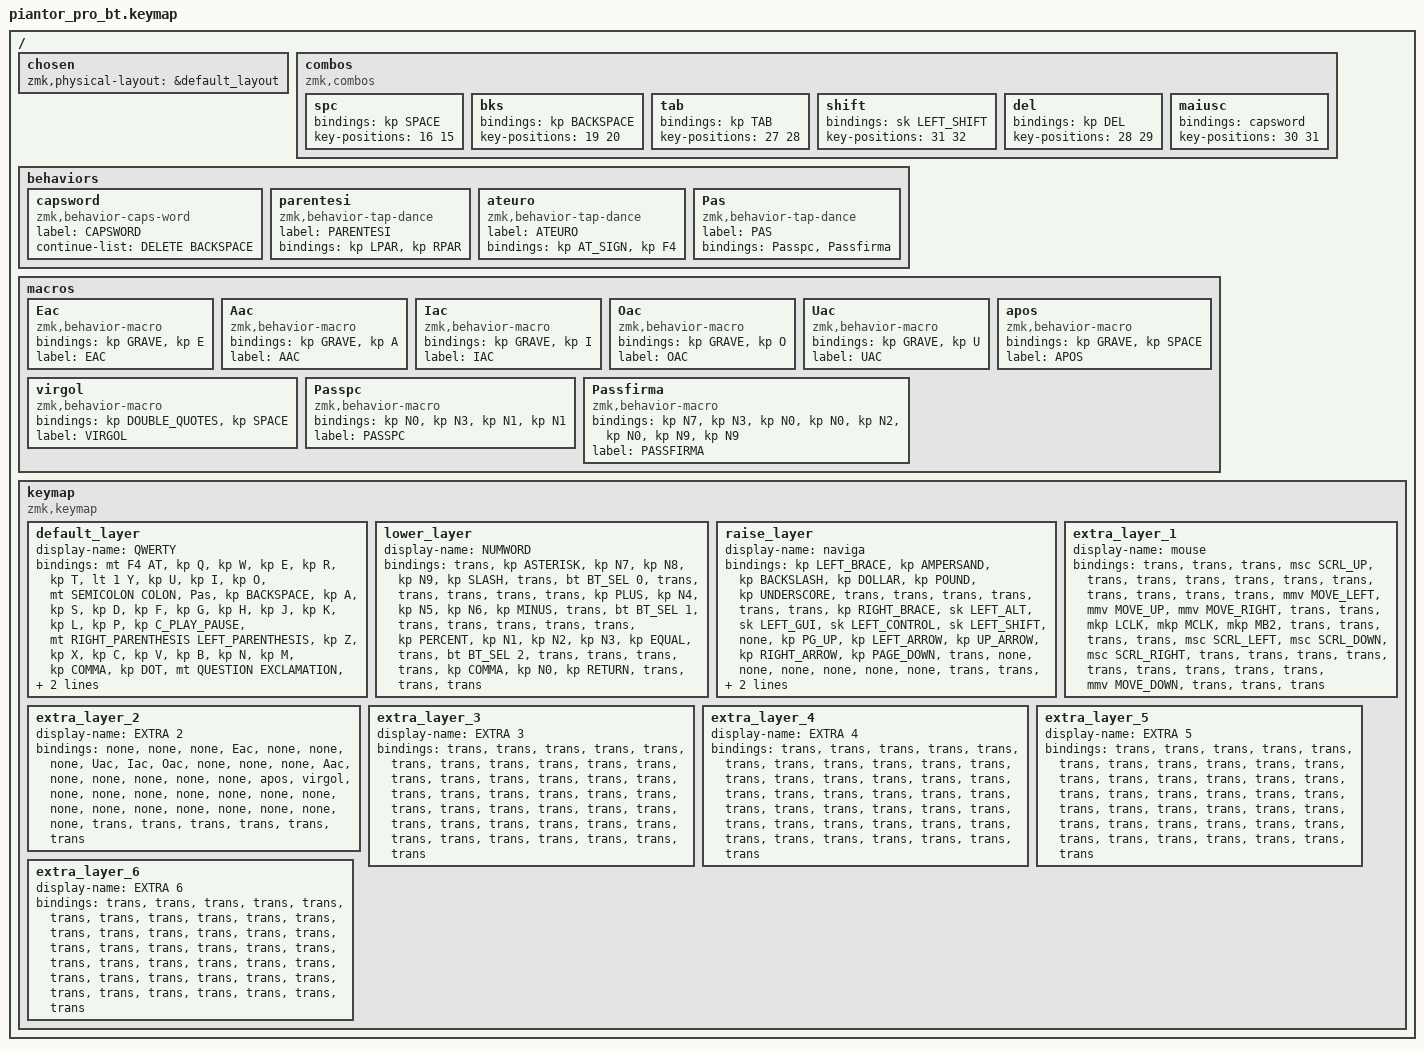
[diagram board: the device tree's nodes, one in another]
/*
 * Copyright (c) 2020 The ZMK Contributors
 *
 * SPDX-License-Identifier: MIT
 */

#define ZMK_POINTING_DEFAULT_MOVE_VAL 1500  // default: 600
#define ZMK_POINTING_DEFAULT_SCRL_VAL 20    // default: 10

#include <behaviors/num_word.dtsi>
#include <behaviors/num_word.dtsi>
#include <behaviors.dtsi>
#include <dt-bindings/zmk/bt.h>
#include <dt-bindings/zmk/keys.h>
#include <dt-bindings/zmk/pointing.h>

/ {
    chosen { zmk,physical-layout = &default_layout; };
};

/ {
    combos {
        compatible = "zmk,combos";

        spc {
            bindings = <&kp SPACE>;
            key-positions = <16 15>;
        };

        bks {
            bindings = <&kp BACKSPACE>;
            key-positions = <19 20>;
        };

        tab {
            bindings = <&kp TAB>;
            key-positions = <27 28>;
        };

        shift {
            bindings = <&sk LEFT_SHIFT>;
            key-positions = <31 32>;
        };

        del {
            bindings = <&kp DEL>;
            key-positions = <28 29>;
        };

        maiusc {
            bindings = <&capsword>;
            key-positions = <30 31>;
        };
    };

    behaviors {
        capsword: capsword {
            compatible = "zmk,behavior-caps-word";
            label = "CAPSWORD";
            #binding-cells = <0>;
            continue-list = <DELETE BACKSPACE>;
        };

        parentesi: parentesi {
            compatible = "zmk,behavior-tap-dance";
            label = "PARENTESI";
            #binding-cells = <0>;
            bindings = <&kp LPAR>, <&kp RPAR>;
        };

        ateuro: ateuro {
            compatible = "zmk,behavior-tap-dance";
            label = "ATEURO";
            #binding-cells = <0>;
            bindings = <&kp AT_SIGN>, <&kp F4>;
        };

        Pas: Pas {
            compatible = "zmk,behavior-tap-dance";
            label = "PAS";
            #binding-cells = <0>;
            bindings = <&Passpc>, <&Passfirma>;
        };
    };

    behaviors {
    };

    macros {
        Eac: Eac {
            compatible = "zmk,behavior-macro";
            #binding-cells = <0>;
            bindings = <&kp GRAVE &kp E>;
            label = "EAC";
        };

        Aac: Aac {
            compatible = "zmk,behavior-macro";
            #binding-cells = <0>;
            bindings = <&kp GRAVE &kp A>;
            label = "AAC";
        };

        Iac: Iac {
            compatible = "zmk,behavior-macro";
            #binding-cells = <0>;
            bindings = <&kp GRAVE &kp I>;
            label = "IAC";
        };

        Oac: Oac {
            compatible = "zmk,behavior-macro";
            #binding-cells = <0>;
            bindings = <&kp GRAVE &kp O>;
            label = "OAC";
        };

        Uac: Uac {
            compatible = "zmk,behavior-macro";
            #binding-cells = <0>;
            bindings = <&kp GRAVE &kp U>;
            label = "UAC";
        };

        apos: apos {
            compatible = "zmk,behavior-macro";
            #binding-cells = <0>;
            bindings = <&kp GRAVE &kp SPACE>;
            label = "APOS";
        };

        virgol: virgol {
            compatible = "zmk,behavior-macro";
            #binding-cells = <0>;
            bindings = <&kp DOUBLE_QUOTES &kp SPACE>;
            label = "VIRGOL";
        };

        Passpc: Passpc {
            compatible = "zmk,behavior-macro";
            #binding-cells = <0>;
            bindings = <&kp N0 &kp N3 &kp N1 &kp N1>;
            label = "PASSPC";
        };

        Passfirma: Passfirma {
            compatible = "zmk,behavior-macro";
            #binding-cells = <0>;
            bindings = <&kp N7 &kp N3 &kp N0 &kp N0 &kp N2 &kp N0 &kp N9 &kp N9>;
            label = "PASSFIRMA";
        };
    };

    keymap {
        compatible = "zmk,keymap";

        default_layer {
            display-name = "QWERTY";

            // --------------------------------------------------------------------------------
            // |  TAB |  Q  |  W  |  E  |  R  |  T  |  Y  |  U   |  I  |  O  |  P  | BSPC |
            // | CTRL |  A  |  S  |  D  |  F  |  G  |  H  |  J   |  K  |  L  |  ;  |  '   |
            // | SHFT |  Z  |  X  |  C  |  V  |  B  |  N  |  M   |  ,  |  .  |  /  | ESC  |
            //                    | GUI | LWR | SPC | ENT | RSE  | ALT |

            bindings = <
&mt F4 AT  &kp Q  &kp W  &kp E  &kp R  &kp T  &lt 1 Y  &kp U  &kp I  &kp O  &mt SEMICOLON COLON  &Pas  &kp BACKSPACE  &kp A  &kp S  &kp D  &kp F  &kp G  &kp H  &kp J  &kp K  &kp L  &kp P  &kp C_PLAY_PAUSE  &mt RIGHT_PARENTHESIS LEFT_PARENTHESIS  &kp Z  &kp X  &kp C  &kp V  &kp B  &kp N  &kp M  &kp COMMA  &kp DOT  &mt QUESTION EXCLAMATION  &mt C_VOLUME_UP C_VOL_DN  &num_word 1  &kp ESC  &lt 2 ENTER  &sl 4  &kp LEFT_CONTROL  &tog 3
            >;
        };

        lower_layer {
            display-name = "NUMWORD";

            // -----------------------------------------------------------------------------------------
            // |  TAB |  1  |  2  |  3  |  4  |  5    |  6  |  7  |  8  |  9  |  0  | BSPC |
            // | CTRL | BT1 | BT2 | BT3 | BT4 | BT5   | LFT | DWN |  UP | RGT |     |      |
            // | SHFT | BTCR| RGB | RST | BOOT| Unlock|     |     |     |     |     |      |
            //                    | GUI |     | SPC   | ENT |     | ALT |

            bindings = <
&trans  &kp ASTERISK  &kp N7  &kp N8  &kp N9  &kp SLASH  &trans  &bt BT_SEL 0  &trans  &trans  &trans  &trans  &trans  &kp PLUS  &kp N4  &kp N5  &kp N6  &kp MINUS  &trans  &bt BT_SEL 1  &trans  &trans  &trans  &trans  &trans  &kp PERCENT  &kp N1  &kp N2  &kp N3  &kp EQUAL  &trans  &bt BT_SEL 2  &trans  &trans  &trans  &trans  &kp COMMA  &kp N0  &kp RETURN  &trans  &trans  &trans
            >;
        };

        raise_layer {
            display-name = "naviga";

            // -----------------------------------------------------------------------------------------
            // |  TAB |  !  |  @  |  #  |  $  |  %  |  ^  |  &  |  *  |  (  |  )  | BSPC |
            // | CTRL |     |     |     |     |     |  -  |  =  |  [  |  ]  |  \  |  `   |
            // | SHFT |     |     |     |     |     |  _  |  +  |  {  |  }  | "|" |  ~   |
            //                    | GUI |     | SPC | ENT |     | ALT |

            bindings = <
&kp LEFT_BRACE  &kp AMPERSAND  &kp BACKSLASH  &kp DOLLAR  &kp POUND  &kp UNDERSCORE  &trans  &trans  &trans  &trans  &trans  &trans  &kp RIGHT_BRACE  &sk LEFT_ALT  &sk LEFT_GUI  &sk LEFT_CONTROL  &sk LEFT_SHIFT  &none  &kp PG_UP  &kp LEFT_ARROW  &kp UP_ARROW  &kp RIGHT_ARROW  &kp PAGE_DOWN  &trans  &none  &none  &none  &none  &none  &none  &trans  &trans  &trans  &trans  &trans  &trans  &trans  &trans  &trans  &kp DOWN_ARROW  &trans  &trans
            >;
        };

        extra_layer_1 {
            display-name = "mouse";
            bindings = <
&trans  &trans  &trans  &msc SCRL_UP  &trans  &trans  &trans  &trans  &trans  &trans  &trans  &trans  &trans  &trans  &mmv MOVE_LEFT  &mmv MOVE_UP  &mmv MOVE_RIGHT  &trans  &trans  &mkp LCLK  &mkp MCLK  &mkp MB2  &trans  &trans  &trans  &trans  &msc SCRL_LEFT  &msc SCRL_DOWN  &msc SCRL_RIGHT  &trans  &trans  &trans  &trans  &trans  &trans  &trans  &trans  &trans  &mmv MOVE_DOWN  &trans  &trans  &trans
            >;
        };

        extra_layer_2 {
            display-name = "EXTRA 2";
            bindings = <
&none  &none  &none  &Eac  &none  &none  &none  &Uac  &Iac  &Oac  &none  &none  &none  &Aac  &none  &none  &none  &none  &none  &apos  &virgol  &none  &none  &none  &none  &none  &none  &none  &none  &none  &none  &none  &none  &none  &none  &none  &trans  &trans  &trans  &trans  &trans  &trans
            >;
        };

        extra_layer_3 {
            display-name = "EXTRA 3";
            bindings = <
&trans  &trans  &trans  &trans  &trans  &trans  &trans  &trans  &trans  &trans  &trans  &trans  &trans  &trans  &trans  &trans  &trans  &trans  &trans  &trans  &trans  &trans  &trans  &trans  &trans  &trans  &trans  &trans  &trans  &trans  &trans  &trans  &trans  &trans  &trans  &trans  &trans  &trans  &trans  &trans  &trans  &trans
            >;
        };

        extra_layer_4 {
            display-name = "EXTRA 4";
            bindings = <
&trans  &trans  &trans  &trans  &trans  &trans  &trans  &trans  &trans  &trans  &trans  &trans  &trans  &trans  &trans  &trans  &trans  &trans  &trans  &trans  &trans  &trans  &trans  &trans  &trans  &trans  &trans  &trans  &trans  &trans  &trans  &trans  &trans  &trans  &trans  &trans  &trans  &trans  &trans  &trans  &trans  &trans
            >;
        };

        extra_layer_5 {
            display-name = "EXTRA 5";
            bindings = <
&trans  &trans  &trans  &trans  &trans  &trans  &trans  &trans  &trans  &trans  &trans  &trans  &trans  &trans  &trans  &trans  &trans  &trans  &trans  &trans  &trans  &trans  &trans  &trans  &trans  &trans  &trans  &trans  &trans  &trans  &trans  &trans  &trans  &trans  &trans  &trans  &trans  &trans  &trans  &trans  &trans  &trans
            >;
        };

        extra_layer_6 {
            display-name = "EXTRA 6";
            bindings = <
&trans  &trans  &trans  &trans  &trans  &trans  &trans  &trans  &trans  &trans  &trans  &trans  &trans  &trans  &trans  &trans  &trans  &trans  &trans  &trans  &trans  &trans  &trans  &trans  &trans  &trans  &trans  &trans  &trans  &trans  &trans  &trans  &trans  &trans  &trans  &trans  &trans  &trans  &trans  &trans  &trans  &trans
            >;
        };
    };
};
